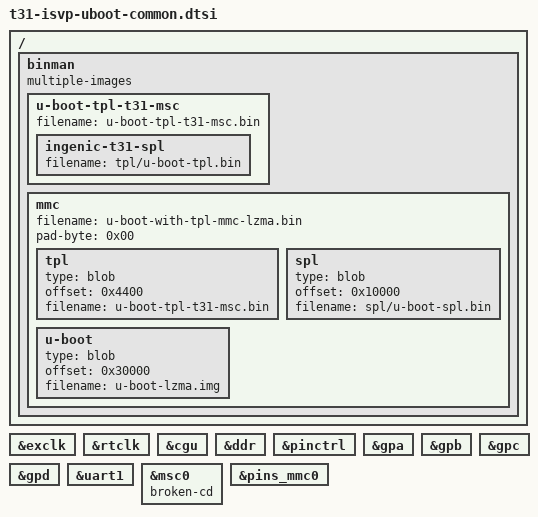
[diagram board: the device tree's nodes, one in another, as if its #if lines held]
// SPDX-License-Identifier: GPL-2.0+
/*
 * Shared U-Boot overlay for the Ingenic ISVP-T31 SFC-NOR leaf DTs.
 * Each per-SKU <leaf>-u-boot.dtsi is a one-line #include of this file
 * (the U-Boot build auto-appends <leaf>-u-boot.dtsi to <leaf>.dts).
 *
 * T31 boots a TPL chain. Its NOR mask ROM is uncapped, but the SD-card ROM
 * runs the first stage in a cache-lock window that cannot hold the SPL once it
 * carries the DM + SFC/MMC stack - so, like every XBurst1 SoC, the bring-up is
 * split: the ROM loads the headered TPL (NOR offset 0, or SD sector 34); the
 * TPL brings up DDR in cache-as-RAM and reads the DRAM-resident SPL (NOR 0x8000,
 * or SD 0x10000); the SPL reads U-Boot (NOR 0x18000 = CONFIG_SYS_SPI_U_BOOT_OFFS,
 * or SD 0x30000). The 2 KiB header CRC7+length is finalized by the family-
 * generic ingenic-t31-spl binman etype.
 *
 * Phase tags: the TPL/SPL devicetrees are fdtgrep-filtered out of the single
 * dt.dtb by bootph tags (TPL keeps bootph-all + bootph-pre-sram; SPL keeps
 * bootph-all + bootph-pre-ram), NOT re-preprocessed per phase. The TPL's only
 * DM device is &ddr (its probe brings up PLL + DDR, then it hand-loads the SPL
 * with bare-metal SFC/serial helpers), so only &ddr is tagged for all phases;
 * every other node is bootph-pre-ram + bootph-some-ram (present in the SPL DM
 * boot and U-Boot pre-reloc, absent from the minimal TPL).
 */

/ {
	binman: binman {
		multiple-images;
	};
};

&binman {
#if defined(CONFIG_SPL_MMC)
	/*
	 * MSC/SD-card boot image (isvp_t31x_msc0). The XBurst1 SD ROM reads the
	 * headered first stage (the TPL) off the card, checks the MSPL magic and
	 * jumps to it. The TPL reprograms MSC0CDR for its own bare-metal SPL read
	 * (the shared xburst_tpl_msc_read), brings up DDR, loads the DRAM-resident
	 * SPL and jumps; the SPL then probes DM MMC to load U-Boot. SD layout: TPL
	 * at sector 34 (0x4400), the DRAM-resident SPL at 0x10000, U-Boot at
	 * SYS_MMCSD_RAW_MODE_U_BOOT_SECTOR (0x180 = 0x30000).
	 */
	u-boot-tpl-t31-msc {
		filename = "u-boot-tpl-t31-msc.bin";

		ingenic-t31-spl {
			filename = "tpl/u-boot-tpl.bin";
		};
	};

	mmc {
		filename = "u-boot-with-tpl-mmc-lzma.bin";
		pad-byte = <0x00>;

		tpl {
			type = "blob";
			offset = <0x4400>;
			filename = "u-boot-tpl-t31-msc.bin";
		};

		spl {
			type = "blob";
			offset = <0x10000>;
			filename = "spl/u-boot-spl.bin";
		};

		u-boot {
			type = "blob";
			offset = <0x30000>;
			filename = "u-boot-lzma.img";
		};
	};
#elif defined(CONFIG_TPL)
	u-boot-tpl-t31 {
		filename = "u-boot-tpl-t31.bin";

		ingenic-t31-spl {
			filename = "tpl/u-boot-tpl.bin";
		};
	};

	flash {
		filename = "u-boot-with-tpl-lzma.bin";
		pad-byte = <0xff>;

		tpl {
			type = "blob";
			offset = <0x0>;
			filename = "u-boot-tpl-t31.bin";
		};

		spl {
			type = "blob";
			offset = <0x8000>;
			filename = "spl/u-boot-spl.bin";
		};

		u-boot {
			type = "blob";
			offset = <0x18000>;
			filename = "u-boot-lzma.img";
		};
	};
#else
	u-boot-spl-t31 {
		filename = "u-boot-spl-t31.bin";

		ingenic-t31-spl {
			filename = "spl/u-boot-spl.bin";
		};
	};

	flash {
		filename = "u-boot-with-spl-lzma.bin";
		pad-byte = <0xff>;

		spl {
			type = "blob";
			offset = <0x0>;
			filename = "u-boot-spl-t31.bin";
		};

		u-boot {
			type = "blob";
			offset = <0x14000>;
			filename = "u-boot-lzma.img";
		};
	};
#endif
};

&exclk { bootph-pre-ram; bootph-some-ram; };
&rtclk { bootph-pre-ram; bootph-some-ram; };
&cgu { bootph-pre-ram; bootph-some-ram; };
&ddr { bootph-all; };		/* the TPL's only DM device; leaf supplies params */
&pinctrl { bootph-pre-ram; bootph-some-ram; };
&gpa { bootph-pre-ram; bootph-some-ram; };
&gpb { bootph-pre-ram; bootph-some-ram; };
&gpc { bootph-pre-ram; bootph-some-ram; };
&gpd { bootph-pre-ram; bootph-some-ram; };
&uart1 { bootph-pre-ram; bootph-some-ram; };

#if defined(CONFIG_SPL_MMC)
/*
 * MSC/SD boot: the SPL probes the native jz_mmc controller (the TPL's SD
 * read is bare-metal, so the TPL devicetree still needs only &ddr). msc0 is
 * status="disabled" in t31.dtsi - the NOR boards never use it - so enable it
 * here and tag it + its pins for the SPL and pre-reloc U-Boot phases.
 */
&msc0 {
	bootph-pre-ram;
	bootph-some-ram;
	broken-cd;		/* the SD is the boot medium - always present */
	status = "okay";
};
&pins_mmc0 { bootph-pre-ram; bootph-some-ram; };
#else
&pins_sfc { bootph-pre-ram; bootph-some-ram; };
&sfc {
	bootph-pre-ram;
	bootph-some-ram;
	flash@0 {
		bootph-pre-ram;
		bootph-some-ram;
	};
};
#endif
